# PT32x060xx register map
File version: 0.1
Registers are 32-bit, read-write, reset 0x0 unless marked. A register's access mark holds for its fields unless they carry their own. Offsets are from the block's base; [hi:lo] are bit positions; {n}, {i} and the like mark numbered series; 'fields as' and 'values as' point back to an identical list.

## GPIOA — General purpose I/O
Base 0x48000000
Same registers: GPIOB 0x48001000, GPIOC 0x48002000, GPIOD 0x48003000, GPIOE 0x48004000
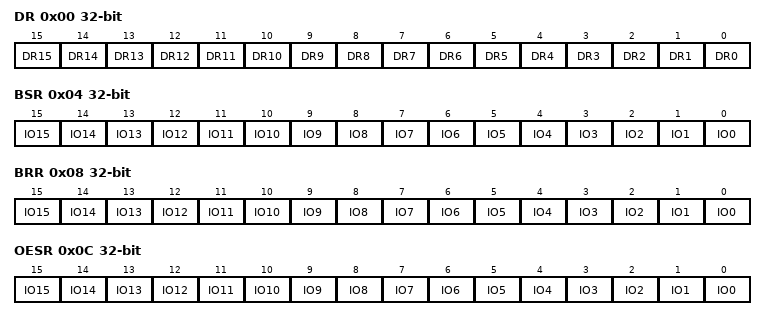
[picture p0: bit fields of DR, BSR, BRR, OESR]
0x00 DR — Port Data Register
  [n] DR{n} (n=0..15) — Port x pin {n} data
0x04 BSR wo — Port Bit Set Register
  [n] IO{n} (n=0..15) — Port x set bit {n}
0x08 BRR wo — Port Bit Reset Register
  [n] IO{n} (n=0..15) — Port x reset bit {n}
0x0C OESR — Output Enable Set Register
  [n] IO{n} (n=0..15) — Port x pin {n} output enable
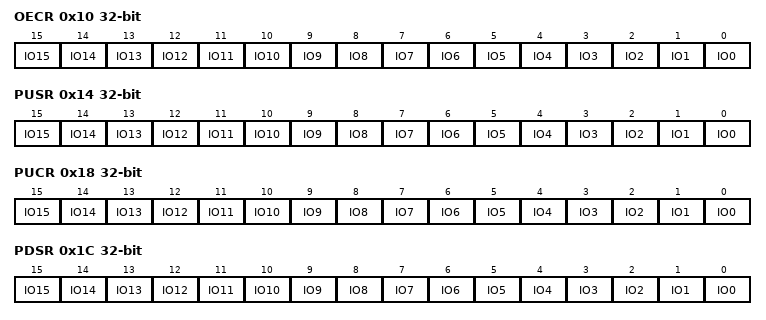
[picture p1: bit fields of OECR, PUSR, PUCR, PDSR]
0x10 OECR wo — Output Enable Clear Register
  [n] IO{n} (n=0..15) — Port x pin {n} output disable
0x14 PUSR — Pull-Up Set Register
  [n] IO{n} (n=0..15) — Port x pin {n} input pull-up enable
0x18 PUCR wo — Pull-Up Clear Register
  [n] IO{n} (n=0..15) — Port x pin {n} input pull-up disable
0x1C PDSR — Pull-Down Set Register
  [n] IO{n} (n=0..15) — Port x pin {n} input pull-down enable
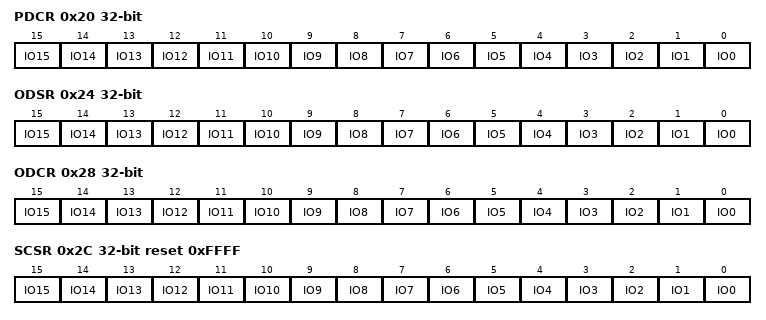
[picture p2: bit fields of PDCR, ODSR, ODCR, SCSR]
0x20 PDCR wo — Pull-Down Clear Register
  [n] IO{n} (n=0..15) — Port x pin {n} input pull-down disable
0x24 ODSR — Output Open-Drain Set Register
  [n] IO{n} (n=0..15) — Port x pin {n} output open-drain enable
0x28 ODCR wo — Output Open-Drain Clear Register
  [n] IO{n} (n=0..15) — Port x pin {n} output open-drain disable
0x2C SCSR reset 0xFFFF — Input Schmitt Set Register
  [n] IO{n} (n=0..15) — Port x pin {n} input Schmitt trigger enable
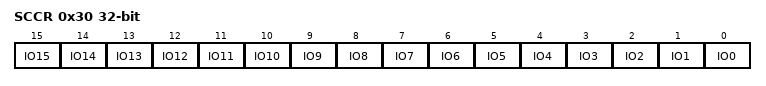
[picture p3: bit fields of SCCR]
0x30 SCCR wo — Input Schmitt Clear Register
  [n] IO{n} (n=0..15) — Port x pin {n} input Schmitt trigger disable

## AFIOA — Alternate function
Base 0x48000100
Same registers: AFIOB 0x48001100, AFIOC 0x48002100, AFIOD 0x48003100, AFIOE 0x48004100
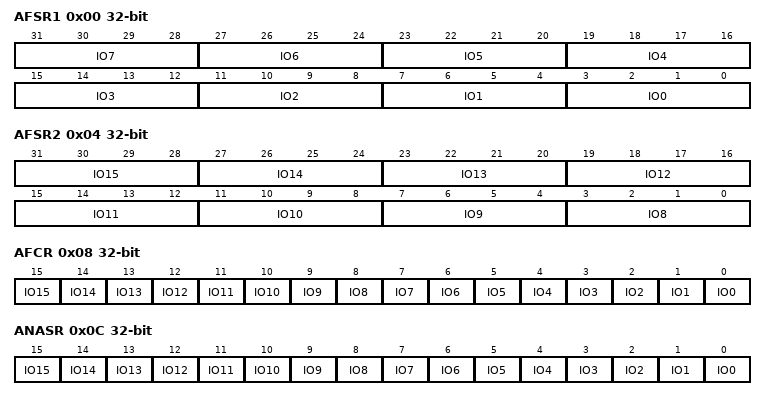
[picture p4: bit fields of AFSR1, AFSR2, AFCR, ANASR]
0x00 AFSR1 — Digtal Alternate Function Set Register 1
  [4n+3:4n] IO{n} (n=0..7) — Port x pin {n} digtal alternate function
0x04 AFSR2 — Digtal Alternate Function Set Register 2
  [4n-29:4n-32] IO{n} (n=8..15) — Port x pin {n} digtal alternate function
0x08 AFCR wo — Digtal Alternate Function Clear Register
  [n] IO{n} (n=0..15) — Port x pin {n} digtal alternate function clear
0x0C ANASR — Analog Alternate Function Set Register
  [n] IO{n} (n=0..15) — Port x pin {n} analog alternate function
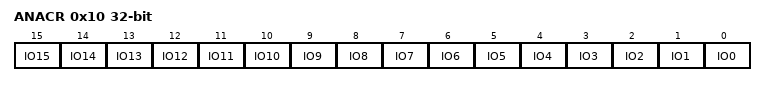
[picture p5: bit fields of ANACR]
0x10 ANACR wo — Analog Alternate Function Clear Register
  [n] IO{n} (n=0..15) — Port x pin {n} analog alternate function clear

## EXTIA — External interrupt
Base 0x48000200
Same registers: EXTIB 0x48001200, EXTIC 0x48002200, EXTID 0x48003200, EXTIE 0x48004200
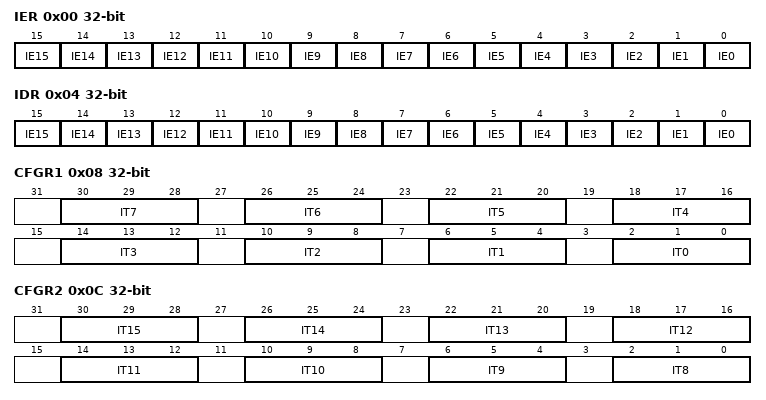
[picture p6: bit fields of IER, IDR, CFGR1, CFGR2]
0x00 IER — Interrupt Enable Register
  [n] IE{n} (n=0..15) — port x pin {n} input interrupt enable
0x04 IDR wo — Interrupt Disable Register
  [n] IE{n} (n=0..15) — port x pin {n} input interrupt disable
0x08 CFGR1 — Interrupt Type Configuration Register 1
  [4n+2:4n] IT{n} (n=0..7) — port x pin {n} input interrupt type
0x0C CFGR2 — Interrupt Type Configuration Register2
  [4n-30:4n-32] IT{n} (n=8..15) — port x pin {n} input interrupt type
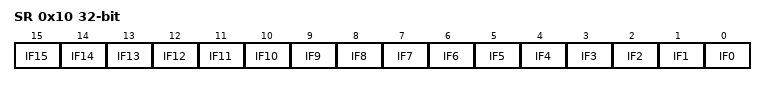
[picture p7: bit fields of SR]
0x10 SR — Interrupt Status Register
  [n] IF{n} (n=0..15) — port x pin {n} input interrupt flag

## DMA — Direct memory access
Base 0x4000F000
0x00 C0SBAR — Channel 0 Source Base Address Register
  [31:0] SBA — DMA source base address
0x04 C0DBAR — Channel 0 Destination Base Address Register
  [31:0] DBA — DMA destination base address
0x08 C0NDTR — Channel 0 Number of Data To Transfer Register
  [15:0] NDT — Number of data to transfer
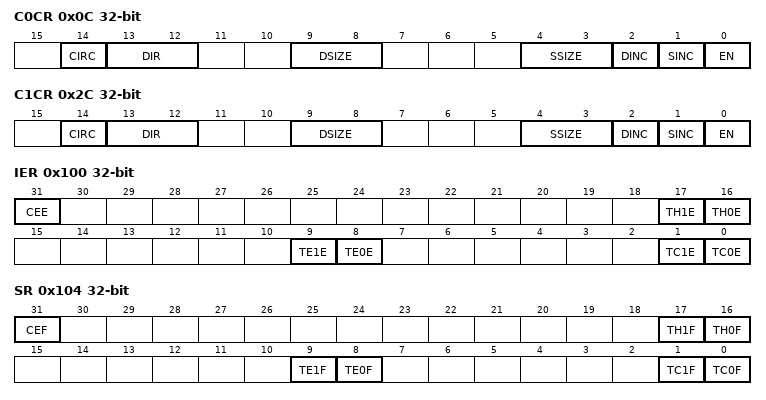
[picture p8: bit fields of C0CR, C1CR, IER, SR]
0x0C C0CR — Channel 0 Control Register
  [14] CIRC — Circular mode
  [13:12] DIR — Direction
  [9:8] DSIZE — Destination data size
  [4:3] SSIZE — Source data size
  [2] DINC — Destination address increment control
  [1] SINC — Source address increment control
  [0] EN — DMA channel enable
0x10 C0CSAR ro — Channel 0 Current Source Address Register
  [31:0] CSA — DMA current source address
0x14 C0CDAR ro — Channel 0 Current Destination Address Register
  [31:0] CDA — DMA current destination address
0x18 C0CNTR ro — Channel 0 Counter Register
  [15:0] CNT — Counter value
0x20 C1SBAR — Channel 1 Source Base Address Register
  [31:0] SBA — DMA source base address
0x24 C1DBAR — Channel 1 Destination Base Address Register
  [31:0] DBA — DMA destination base address
0x28 C1NDTR — Channel 1 Number of Data To Transfer Register
  [15:0] NDT — Number of data to transfer
0x2C C1CR — Channel 1 Control Register
  fields as C0CR
0x30 C1CSAR ro — Channel 1 Current Source Address Register
  [31:0] CSA — DMA current source address
0x34 C1CDAR ro — Channel 1 Current Destination Address Register
  [31:0] CDA — DMA current destination address
0x38 C1CNTR ro — Channel 1 Counter Register
  [15:0] CNT — Counter value
0x100 IER — Interrupt Enable Register
  [31] CEE — DMA channel configuration error interrupt enable
  [17] TH1E — DMA channel 1 transfer over half interrupt enable
  [16] TH0E — DMA channel 0 transfer over half interrupt enable
  [9] TE1E — DMA channel 1 transfer error interrupt enable
  [8] TE0E — DMA channel 0 transfer error interrupt enable
  [1] TC1E — DMA channel 1 transfer complete interrupt enable
  [0] TC0E — DMA channel 0 transfer complete interrupt enable
0x104 SR access per field — Status Register
  [31] CEF ro — DMA channel configuration error flag
  [17] TH1F rw — DMA channel 1 transfer over half interrupt flag
  [16] TH0F rw — DMA channel 0 transfer over half interrupt flag
  [9] TE1F rw — DMA channel 1 transfer error interrupt flag
  [8] TE0F rw — DMA channel 0 transfer error interrupt flag
  [1] TC1F rw — DMA channel 1 transfer complete interrupt flag
  [0] TC0F rw — DMA channel 0 transfer complete interrupt flag
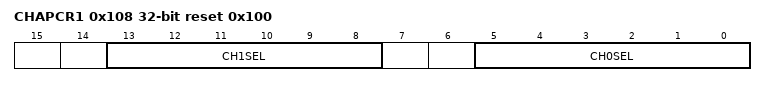
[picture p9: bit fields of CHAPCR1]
0x108 CHAPCR1 reset 0x100 — Channel Associated Peripheral Control Register 1
  [13:8] CH1SEL — DMA channel 1 peripheral selection
  [5:0] CH0SEL — DMA channel 0 peripheral selection
